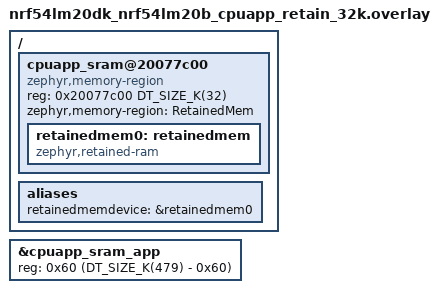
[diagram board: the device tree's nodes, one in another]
/ {
	cpuapp_sram@20077c00 {
		compatible = "zephyr,memory-region", "mmio-sram";
		reg = <0x20077c00 DT_SIZE_K(32)>;
		zephyr,memory-region = "RetainedMem";
		status = "okay";

		retainedmem0: retainedmem {
			compatible = "zephyr,retained-ram";
			status = "okay";
		};
	};

	aliases {
		retainedmemdevice = &retainedmem0;
	};
};

&cpuapp_sram_app {
	/* Shrink SRAM size to avoid overlap with retained memory region:
	 * 511 - 32 = 479KB = 0x77c00
	 */
	reg = <0x60 (DT_SIZE_K(479) - 0x60)>;
};
